AUTOSAR XML (schema 4-2-2)
package /Components
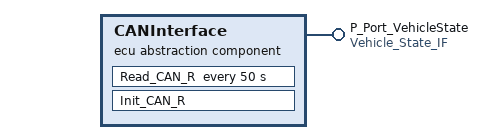
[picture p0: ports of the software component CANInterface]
  ecu abstraction sw component type CANInterface
    provide port P_Port_VehicleState: provided-interface=Vehicle_State_IF
    behavior CANInterface_Internal
      init event CAN_Init: start-on-event=Init_CAN_R
      timing event CAN_Poll: start-on-event=Read_CAN_R, period=50
      runnable Init_CAN_R
        parameter access ParamAccess_SpeedScale: accessed-parameter=P_Port_VehicleState.vehicle_speed_kph
        parameter access ParamAccess_GearMap: accessed-parameter=P_Port_VehicleState.vehicle_gear
      runnable Read_CAN_R: minimum-start-interval=50
        data-send-points:
          access Send_VehicleSpeed: accessed-variable=P_Port_VehicleState.vehicle_speed_kph
          access Send_VehicleGear: accessed-variable=P_Port_VehicleState.vehicle_gear
